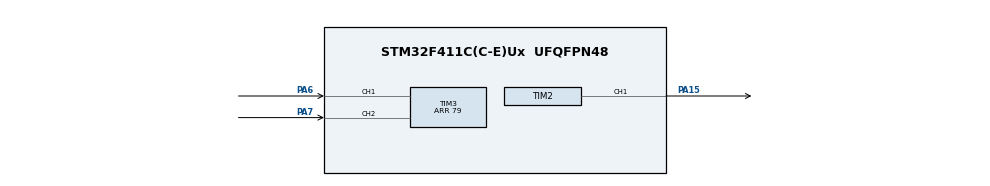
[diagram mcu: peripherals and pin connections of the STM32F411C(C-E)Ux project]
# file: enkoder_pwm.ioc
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Mcu.Family=STM32F4
Mcu.Name=STM32F411C(C-E)Ux
Mcu.Package=UFQFPN48
NVIC.PriorityGroup=NVIC_PRIORITYGROUP_4
NVIC.TIM2_IRQn=true\:0\:0\:false\:false\:true\:true\:true
PA13.Mode=Serial_Wire
PA13.Signal=SYS_JTMS-SWDIO
PA14.Mode=Serial_Wire
PA14.Signal=SYS_JTCK-SWCLK
PA15.Signal=S_TIM2_CH1_ETR
PA6.Signal=S_TIM3_CH1
PA7.Signal=S_TIM3_CH2
PH0\ -\ OSC_IN.Mode=HSE-External-Oscillator
PH0\ -\ OSC_IN.Signal=RCC_OSC_IN
PH1\ -\ OSC_OUT.Mode=HSE-External-Oscillator
PH1\ -\ OSC_OUT.Signal=RCC_OSC_OUT
ProjectManager.HeapSize=0x200
ProjectManager.StackSize=0x400
ProjectManager.TargetToolchain=STM32CubeIDE
RCC.48MHZClocksFreq_Value=50000000
RCC.AHBFreq_Value=100000000
RCC.APB1CLKDivider=RCC_HCLK_DIV2
RCC.APB1Freq_Value=50000000
RCC.APB1TimFreq_Value=100000000
RCC.APB2Freq_Value=100000000
RCC.APB2TimFreq_Value=100000000
RCC.CortexFreq_Value=100000000
RCC.HCLKFreq_Value=100000000
RCC.HSE_VALUE=25000000
RCC.HSI_VALUE=16000000
RCC.LSE_VALUE=32768
RCC.PLLM=12
RCC.PLLN=96
RCC.PLLSourceVirtual=RCC_PLLSOURCE_HSE
RCC.SYSCLKFreq_VALUE=100000000
RCC.SYSCLKSource=RCC_SYSCLKSOURCE_PLLCLK
RCC.VCOOutputFreq_Value=200000000
SH.S_TIM2_CH1_ETR.0=TIM2_CH1,PWM Generation1 CH1
SH.S_TIM3_CH1.0=TIM3_CH1,Encoder_Interface
SH.S_TIM3_CH2.0=TIM3_CH2,Encoder_Interface
TIM2.AutoReloadPreload=TIM_AUTORELOAD_PRELOAD_DISABLE
TIM2.Channel-PWM\ Generation1\ CH1=TIM_CHANNEL_1
TIM2.OCFastMode_PWM-PWM\ Generation1\ CH1=TIM_OCFAST_DISABLE
TIM2.Period=1999
TIM2.Prescaler=0
TIM2.Pulse-PWM\ Generation1\ CH1=0
TIM2.TIM_MasterOutputTrigger=TIM_TRGO_UPDATE
TIM3.CounterMode=TIM_COUNTERMODE_DOWN
TIM3.IC1Polarity=TIM_ICPOLARITY_FALLING
TIM3.IC2Polarity=TIM_ICPOLARITY_FALLING
TIM3.Period=79
VP_TIM2_VS_ClockSourceINT.Mode=Internal
board=custom

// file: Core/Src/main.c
/* USER CODE BEGIN Header */
/**
  ******************************************************************************
  * @file           : main.c
  * @brief          : Main program body
  ******************************************************************************
  * @attention
  *
  * <h2><center>&copy; Copyright (c) 2021 STMicroelectronics.
  * All rights reserved.</center></h2>
  *
  * This software component is licensed by ST under BSD 3-Clause license,
  * the "License"; You may not use this file except in compliance with the
  * License. You may obtain a copy of the License at:
  *                        opensource.org/licenses/BSD-3-Clause
  *
  ******************************************************************************
  */
/* USER CODE END Header */
#include "main.h"

void SystemClock_Config(void);
static void MX_GPIO_Init(void);
static void MX_TIM2_Init(void);
static void MX_TIM3_Init(void);

int main(void)
{

  /* MCU Configuration--------------------------------------------------------*/

  /* Reset of all peripherals, Initializes the Flash interface and the Systick. */

  LL_APB2_GRP1_EnableClock(LL_APB2_GRP1_PERIPH_SYSCFG);
  LL_APB1_GRP1_EnableClock(LL_APB1_GRP1_PERIPH_PWR);

  NVIC_SetPriorityGrouping(NVIC_PRIORITYGROUP_4);

  /* System interrupt init*/

  /* Configure the system clock */
  SystemClock_Config();

  /* Initialize all configured peripherals */
  MX_GPIO_Init();
  MX_TIM2_Init();
  MX_TIM3_Init();
  /* USER CODE BEGIN 2 */
  LL_TIM_EnableCounter(TIM3);
  LL_TIM_CC_EnableChannel(TIM2, LL_TIM_CHANNEL_CH1);
//  LL_TIM_EnableUpdateEvent(TIM2);
  LL_TIM_EnableIT_UPDATE(TIM2);
  LL_TIM_EnableCounter(TIM2);
  TIM3->CNT=79;
  /* USER CODE END 2 */

  /* Infinite loop */
  while (1)
  {

  }
}

void SystemClock_Config(void)
{
  LL_FLASH_SetLatency(LL_FLASH_LATENCY_3);
  while(LL_FLASH_GetLatency()!= LL_FLASH_LATENCY_3)
  {
  }
  LL_PWR_SetRegulVoltageScaling(LL_PWR_REGU_VOLTAGE_SCALE1);
  LL_RCC_HSE_Enable();

   /* Wait till HSE is ready */
  while(LL_RCC_HSE_IsReady() != 1)
  {

  }
  LL_RCC_PLL_ConfigDomain_SYS(LL_RCC_PLLSOURCE_HSE, LL_RCC_PLLM_DIV_12, 96, LL_RCC_PLLP_DIV_2);
  LL_RCC_PLL_Enable();

   /* Wait till PLL is ready */
  while(LL_RCC_PLL_IsReady() != 1)
  {

  }
  LL_RCC_SetAHBPrescaler(LL_RCC_SYSCLK_DIV_1);
  LL_RCC_SetAPB1Prescaler(LL_RCC_APB1_DIV_2);
  LL_RCC_SetAPB2Prescaler(LL_RCC_APB2_DIV_1);
  LL_RCC_SetSysClkSource(LL_RCC_SYS_CLKSOURCE_PLL);

   /* Wait till System clock is ready */
  while(LL_RCC_GetSysClkSource() != LL_RCC_SYS_CLKSOURCE_STATUS_PLL)
  {

  }
  LL_Init1msTick(100000000);
  LL_SetSystemCoreClock(100000000);
  LL_RCC_SetTIMPrescaler(LL_RCC_TIM_PRESCALER_TWICE);
}

static void MX_TIM2_Init(void)
{

  LL_TIM_InitTypeDef TIM_InitStruct = {0};
  LL_TIM_OC_InitTypeDef TIM_OC_InitStruct = {0};

  LL_GPIO_InitTypeDef GPIO_InitStruct = {0};

  /* Peripheral clock enable */
  LL_APB1_GRP1_EnableClock(LL_APB1_GRP1_PERIPH_TIM2);

  /* TIM2 interrupt Init */
  NVIC_SetPriority(TIM2_IRQn, NVIC_EncodePriority(NVIC_GetPriorityGrouping(),0, 0));
  NVIC_EnableIRQ(TIM2_IRQn);

  TIM_InitStruct.Prescaler = 0;
  TIM_InitStruct.CounterMode = LL_TIM_COUNTERMODE_UP;
  TIM_InitStruct.Autoreload = 1999;
  TIM_InitStruct.ClockDivision = LL_TIM_CLOCKDIVISION_DIV1;
  LL_TIM_Init(TIM2, &TIM_InitStruct);
  LL_TIM_DisableARRPreload(TIM2);
  LL_TIM_SetClockSource(TIM2, LL_TIM_CLOCKSOURCE_INTERNAL);
  LL_TIM_OC_EnablePreload(TIM2, LL_TIM_CHANNEL_CH1);
  TIM_OC_InitStruct.OCMode = LL_TIM_OCMODE_PWM1;
  TIM_OC_InitStruct.OCState = LL_TIM_OCSTATE_DISABLE;
  TIM_OC_InitStruct.OCNState = LL_TIM_OCSTATE_DISABLE;
  TIM_OC_InitStruct.CompareValue = 0;
  TIM_OC_InitStruct.OCPolarity = LL_TIM_OCPOLARITY_HIGH;
  LL_TIM_OC_Init(TIM2, LL_TIM_CHANNEL_CH1, &TIM_OC_InitStruct);
  LL_TIM_OC_DisableFast(TIM2, LL_TIM_CHANNEL_CH1);
  LL_TIM_SetTriggerOutput(TIM2, LL_TIM_TRGO_UPDATE);
  LL_TIM_DisableMasterSlaveMode(TIM2);
  LL_AHB1_GRP1_EnableClock(LL_AHB1_GRP1_PERIPH_GPIOA);
  /**TIM2 GPIO Configuration
  PA15   ------> TIM2_CH1
  */
  GPIO_InitStruct.Pin = LL_GPIO_PIN_15;
  GPIO_InitStruct.Mode = LL_GPIO_MODE_ALTERNATE;
  GPIO_InitStruct.Speed = LL_GPIO_SPEED_FREQ_LOW;
  GPIO_InitStruct.OutputType = LL_GPIO_OUTPUT_PUSHPULL;
  GPIO_InitStruct.Pull = LL_GPIO_PULL_NO;
  GPIO_InitStruct.Alternate = LL_GPIO_AF_1;
  LL_GPIO_Init(GPIOA, &GPIO_InitStruct);

}

static void MX_TIM3_Init(void)
{

  LL_TIM_InitTypeDef TIM_InitStruct = {0};

  LL_GPIO_InitTypeDef GPIO_InitStruct = {0};

  /* Peripheral clock enable */
  LL_APB1_GRP1_EnableClock(LL_APB1_GRP1_PERIPH_TIM3);

  LL_AHB1_GRP1_EnableClock(LL_AHB1_GRP1_PERIPH_GPIOA);
  /**TIM3 GPIO Configuration
  PA6   ------> TIM3_CH1
  PA7   ------> TIM3_CH2
  */
  GPIO_InitStruct.Pin = LL_GPIO_PIN_6|LL_GPIO_PIN_7;
  GPIO_InitStruct.Mode = LL_GPIO_MODE_ALTERNATE;
  GPIO_InitStruct.Speed = LL_GPIO_SPEED_FREQ_LOW;
  GPIO_InitStruct.OutputType = LL_GPIO_OUTPUT_PUSHPULL;
  GPIO_InitStruct.Pull = LL_GPIO_PULL_NO;
  GPIO_InitStruct.Alternate = LL_GPIO_AF_2;
  LL_GPIO_Init(GPIOA, &GPIO_InitStruct);

  LL_TIM_SetEncoderMode(TIM3, LL_TIM_ENCODERMODE_X2_TI1);
  LL_TIM_IC_SetActiveInput(TIM3, LL_TIM_CHANNEL_CH1, LL_TIM_ACTIVEINPUT_DIRECTTI);
  LL_TIM_IC_SetPrescaler(TIM3, LL_TIM_CHANNEL_CH1, LL_TIM_ICPSC_DIV1);
  LL_TIM_IC_SetFilter(TIM3, LL_TIM_CHANNEL_CH1, LL_TIM_IC_FILTER_FDIV1);
  LL_TIM_IC_SetPolarity(TIM3, LL_TIM_CHANNEL_CH1, LL_TIM_IC_POLARITY_FALLING);
  LL_TIM_IC_SetActiveInput(TIM3, LL_TIM_CHANNEL_CH2, LL_TIM_ACTIVEINPUT_DIRECTTI);
  LL_TIM_IC_SetPrescaler(TIM3, LL_TIM_CHANNEL_CH2, LL_TIM_ICPSC_DIV1);
  LL_TIM_IC_SetFilter(TIM3, LL_TIM_CHANNEL_CH2, LL_TIM_IC_FILTER_FDIV1);
  LL_TIM_IC_SetPolarity(TIM3, LL_TIM_CHANNEL_CH2, LL_TIM_IC_POLARITY_FALLING);
  TIM_InitStruct.Prescaler = 0;
  TIM_InitStruct.CounterMode = LL_TIM_COUNTERMODE_DOWN;
  TIM_InitStruct.Autoreload = 79;
  TIM_InitStruct.ClockDivision = LL_TIM_CLOCKDIVISION_DIV1;
  LL_TIM_Init(TIM3, &TIM_InitStruct);
  LL_TIM_DisableARRPreload(TIM3);
  LL_TIM_SetTriggerOutput(TIM3, LL_TIM_TRGO_RESET);
  LL_TIM_DisableMasterSlaveMode(TIM3);

}

static void MX_GPIO_Init(void)
{

  /* GPIO Ports Clock Enable */
  LL_AHB1_GRP1_EnableClock(LL_AHB1_GRP1_PERIPH_GPIOH);
  LL_AHB1_GRP1_EnableClock(LL_AHB1_GRP1_PERIPH_GPIOA);

}

void Error_Handler(void)
{
  __disable_irq();
  while (1)
  {
  }
}

/************************ (C) COPYRIGHT STMicroelectronics *****END OF FILE****/
